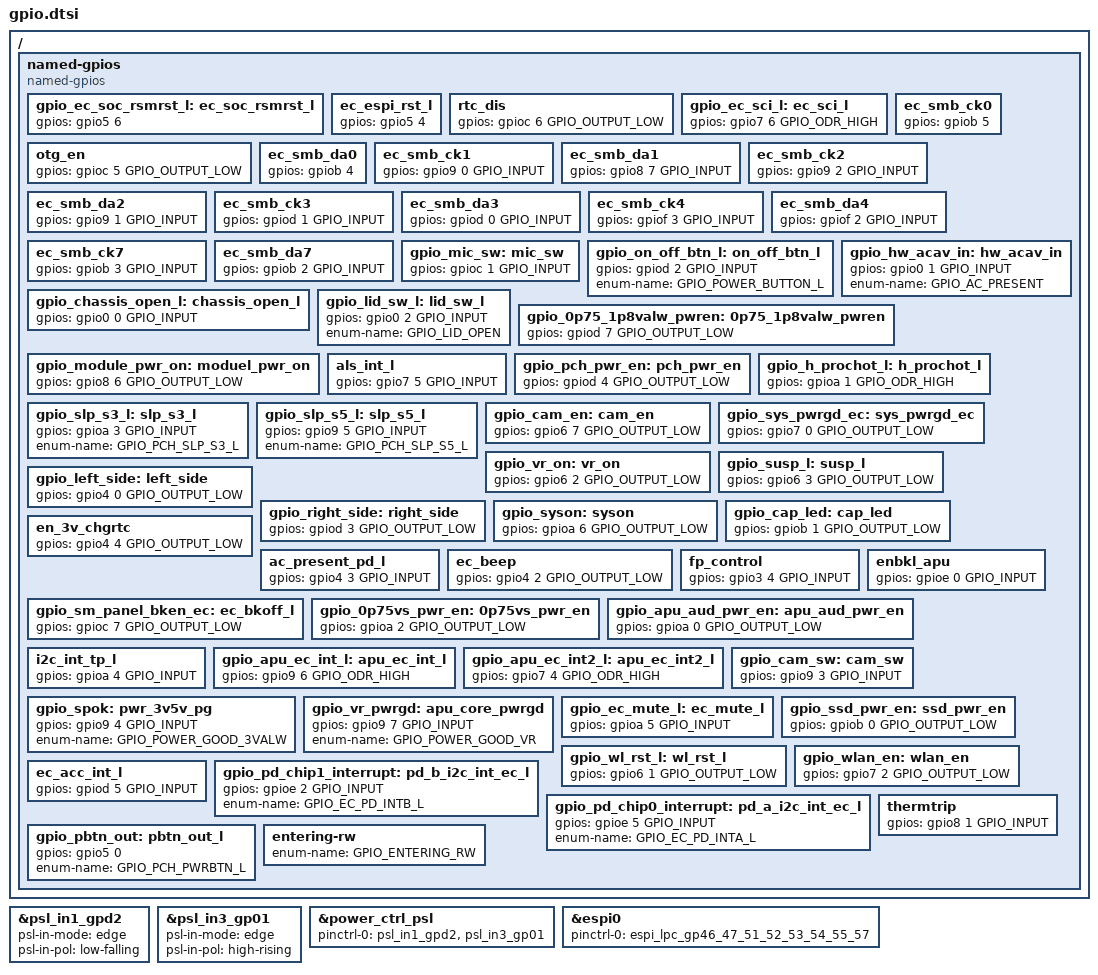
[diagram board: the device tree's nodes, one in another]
/* Copyright 2021 The ChromiumOS Authors
 * Use of this source code is governed by a BSD-style license that can be
 * found in the LICENSE file.
 */

/ {

	named-gpios {
		compatible = "named-gpios";

		gpio_ec_soc_rsmrst_l: ec_soc_rsmrst_l {
			gpios = <&gpio5 6 (GPIO_OUTPUT_LOW | GPIO_VOLTAGE_1P8)>;
		};
		ec_espi_rst_l {
			gpios = <&gpio5 4 (GPIO_INPUT | GPIO_VOLTAGE_1P8)>;
		};
		rtc_dis {
			gpios = <&gpioc 6 GPIO_OUTPUT_LOW>;	/* RTC discharge */
		};
		gpio_ec_sci_l: ec_sci_l {
			gpios = <&gpio7 6 GPIO_ODR_HIGH>;	/* Reserved */
		};
		otg_en {
			gpios = <&gpioc 5 GPIO_OUTPUT_LOW>;
		};
		ec_smb_ck0 {
			gpios = <&gpiob 5 (GPIO_INPUT | GPIO_VOLTAGE_1P8)>;
		};
		ec_smb_da0 {
			gpios = <&gpiob 4 (GPIO_INPUT | GPIO_VOLTAGE_1P8)>;
		};
		ec_smb_ck1 {
			gpios = <&gpio9 0 GPIO_INPUT>;
		};
		ec_smb_da1 {
			gpios = <&gpio8 7 GPIO_INPUT>;
		};
		ec_smb_ck2 {
			gpios = <&gpio9 2 GPIO_INPUT>;
		};
		ec_smb_da2 {
			gpios = <&gpio9 1 GPIO_INPUT>;
		};
		ec_smb_ck3 {
			gpios = <&gpiod 1 GPIO_INPUT>;
		};
		ec_smb_da3 {
			gpios = <&gpiod 0 GPIO_INPUT>;
		};
		ec_smb_ck4 {
			gpios = <&gpiof 3 GPIO_INPUT>;
		};
		ec_smb_da4 {
			gpios = <&gpiof 2 GPIO_INPUT>;
		};
		ec_smb_ck7 {
			gpios = <&gpiob 3 GPIO_INPUT>;
		};
		ec_smb_da7 {
			gpios = <&gpiob 2 GPIO_INPUT>;
		};
		gpio_mic_sw: mic_sw {
			gpios = <&gpioc 1 GPIO_INPUT>;
		};
		gpio_on_off_btn_l: on_off_btn_l {
			gpios = <&gpiod 2 GPIO_INPUT>;		/* PSL in1 signal, power button */
			enum-name = "GPIO_POWER_BUTTON_L";
		};
		gpio_chassis_open_l: chassis_open_l {
			gpios = <&gpio0 0 GPIO_INPUT>;		/* PSL in2 signal, chassis open */
		};
		gpio_hw_acav_in: hw_acav_in {
			gpios = <&gpio0 1 GPIO_INPUT>;		/* PSL in3 signal, ac present pin */
			enum-name = "GPIO_AC_PRESENT";
		};
		gpio_lid_sw_l: lid_sw_l {
			gpios = <&gpio0 2 GPIO_INPUT>;
			enum-name = "GPIO_LID_OPEN";
		};
		gpio_0p75_1p8valw_pwren: 0p75_1p8valw_pwren {
			gpios = <&gpiod 7 GPIO_OUTPUT_LOW>;
		};
		gpio_module_pwr_on: moduel_pwr_on {
			gpios = <&gpio8 6 GPIO_OUTPUT_LOW>;
		};
		als_int_l {
			gpios = <&gpio7 5 GPIO_INPUT>;
		};
		gpio_pch_pwr_en: pch_pwr_en {
			gpios = <&gpiod 4 GPIO_OUTPUT_LOW>;
		};
		gpio_h_prochot_l: h_prochot_l {
			gpios = <&gpioa 1 GPIO_ODR_HIGH>;
		};
		gpio_slp_s3_l: slp_s3_l {
			gpios = <&gpioa 3 GPIO_INPUT>;
			enum-name = "GPIO_PCH_SLP_S3_L";
		};
		gpio_slp_s5_l: slp_s5_l {
			gpios = <&gpio9 5 GPIO_INPUT>;
			enum-name = "GPIO_PCH_SLP_S5_L";
		};
		gpio_cam_en: cam_en {
			gpios = <&gpio6 7 GPIO_OUTPUT_LOW>;
		};
		gpio_sys_pwrgd_ec: sys_pwrgd_ec {
			gpios = <&gpio7 0 GPIO_OUTPUT_LOW>;
		};
		gpio_vr_on: vr_on {
			gpios = <&gpio6 2 GPIO_OUTPUT_LOW>;
		};
		gpio_susp_l: susp_l {
			gpios = <&gpio6 3 GPIO_OUTPUT_LOW>;
		};
		gpio_left_side: left_side {
			gpios = <&gpio4 0 GPIO_OUTPUT_LOW>;	/* left side LED follow IFGA3 */
		};
		gpio_right_side: right_side {
			gpios = <&gpiod 3 GPIO_OUTPUT_LOW>;	/* right side LED follow IFGA3 */
		};
		gpio_syson: syson {
			gpios = <&gpioa 6 GPIO_OUTPUT_LOW>;
		};
		gpio_cap_led: cap_led {
			gpios = <&gpiob 1 GPIO_OUTPUT_LOW>;
		};
		en_3v_chgrtc {
			gpios = <&gpio4 4 GPIO_OUTPUT_LOW>;	/* reserved */
		};
		ac_present_pd_l {
			gpios = <&gpio4 3 GPIO_INPUT>;		/* Monitor AC present from PD */
		};
		ec_beep {
			gpios = <&gpio4 2 GPIO_OUTPUT_LOW>;	/* reserved */
		};
		fp_control {
			gpios = <&gpio3 4 GPIO_INPUT>;		/* Finger Printer feature */
		};
		enbkl_apu {
			gpios = <&gpioe 0 GPIO_INPUT>;		/* monitor APU EDP BKL */
		};
		gpio_sm_panel_bken_ec: ec_bkoff_l {
			gpios = <&gpioc 7 GPIO_OUTPUT_LOW>;
		};
		gpio_0p75vs_pwr_en: 0p75vs_pwr_en {
			gpios = <&gpioa 2 GPIO_OUTPUT_LOW>;
		};
		gpio_apu_aud_pwr_en: apu_aud_pwr_en {
			gpios = <&gpioa 0 GPIO_OUTPUT_LOW>;
		};
		i2c_int_tp_l {
			gpios = <&gpioa 4 GPIO_INPUT>;		/* HUB board TP module */
		};
		gpio_apu_ec_int_l: apu_ec_int_l {
			gpios = <&gpio9 6 GPIO_ODR_HIGH>;	/* EC notify host HID interrupt */
		};
		gpio_apu_ec_int2_l: apu_ec_int2_l {
			gpios = <&gpio7 4 GPIO_ODR_HIGH>;	/* EC notify host HID interrupt 2*/
		};
		gpio_cam_sw: cam_sw {
			gpios = <&gpio9 3 GPIO_INPUT>;
		};
		gpio_spok: pwr_3v5v_pg {
			gpios = <&gpio9 4 GPIO_INPUT>;		/* Monitor 3VALW PWR OK */
			enum-name = "GPIO_POWER_GOOD_3VALW";
		};
		gpio_vr_pwrgd: apu_core_pwrgd {
			gpios = <&gpio9 7 GPIO_INPUT>;
			enum-name = "GPIO_POWER_GOOD_VR";
		};
		gpio_ec_mute_l: ec_mute_l {
			gpios = <&gpioa 5 GPIO_INPUT>;
		};
		gpio_ssd_pwr_en: ssd_pwr_en {
			gpios = <&gpiob 0 GPIO_OUTPUT_LOW>;
		};
		gpio_wl_rst_l: wl_rst_l {
			gpios = <&gpio6 1 GPIO_OUTPUT_LOW>;
		};
		gpio_wlan_en: wlan_en {
			gpios = <&gpio7 2 GPIO_OUTPUT_LOW>;
		};
		ec_acc_int_l {
			gpios = <&gpiod 5 GPIO_INPUT>;
		};
		gpio_pd_chip1_interrupt: pd_b_i2c_int_ec_l {
			gpios = <&gpioe 2 GPIO_INPUT>;
			enum-name = "GPIO_EC_PD_INTB_L";
		};
		gpio_pd_chip0_interrupt: pd_a_i2c_int_ec_l {
			gpios = <&gpioe 5 GPIO_INPUT>;
			enum-name = "GPIO_EC_PD_INTA_L";
		};
		gpio_pbtn_out: pbtn_out_l {
			gpios = <&gpio5 0 (GPIO_ODR_LOW | GPIO_VOLTAGE_1P8)>;
			enum-name = "GPIO_PCH_PWRBTN_L";
		};
		thermtrip {
			gpios = <&gpio8 1 GPIO_INPUT>;
		};

		/* unimplemented GPIOs */
		entering-rw {
			enum-name = "GPIO_ENTERING_RW";
		};
	};
};

/* PSL input pads*/
&psl_in1_gpd2 {
	/* Power button */
	psl-in-mode = "edge";
	psl-in-pol = "low-falling";
};

&psl_in3_gp01 {
	/* ac present */
	psl-in-mode = "edge";
	psl-in-pol = "high-rising";
};

/* Power domain device controlled by PSL (Power Switch Logic) IO pads */
/* Ignored the PSL in 2 (chassis open) at proto phase */
&power_ctrl_psl {
	status = "okay";
	pinctrl-names = "sleep";
	pinctrl-0 = <&psl_in1_gpd2 &psl_in3_gp01>;
};

/* host interface */
&espi0 {
	status = "okay";
	pinctrl-0 = <&espi_lpc_gp46_47_51_52_53_54_55_57>;
	pinctrl-names = "default";
};
